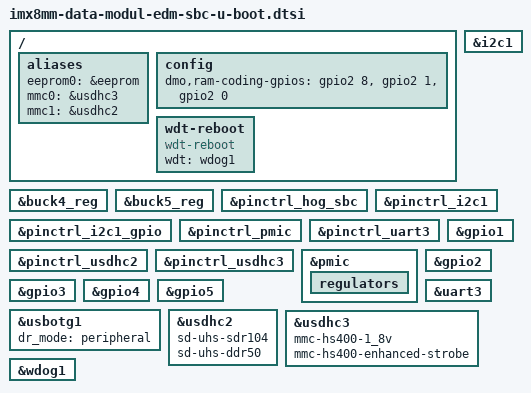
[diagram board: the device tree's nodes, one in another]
// SPDX-License-Identifier: GPL-2.0+
/*
 * Copyright 2022 Marek Vasut <marex@denx.de>
 */

#include "imx8mm-u-boot.dtsi"

/ {
	aliases {
		eeprom0 = &eeprom;
		mmc0 = &usdhc3;	/* eMMC */
		mmc1 = &usdhc2;	/* MicroSD */
	};

	config {
		dmo,ram-coding-gpios = <&gpio2 8 0>, <&gpio2 1 0>, <&gpio2 0 0>;
	};

	wdt-reboot {
		compatible = "wdt-reboot";
		wdt = <&wdog1>;
		bootph-pre-ram;
	};
};

&buck4_reg {
	bootph-pre-ram;
};

&buck5_reg {
	bootph-pre-ram;
};

&i2c1 {
	bootph-pre-ram;
};

&pinctrl_hog_sbc {
	bootph-pre-ram;
};

&pinctrl_i2c1 {
	bootph-pre-ram;
};

&pinctrl_i2c1_gpio {
	bootph-pre-ram;
};

&pinctrl_pmic {
	bootph-pre-ram;
};

&pinctrl_uart3 {
	bootph-pre-ram;
};

&pinctrl_usdhc2 {
	bootph-pre-ram;
};

&pinctrl_usdhc3 {
	bootph-pre-ram;
};

&pmic {
	bootph-pre-ram;

	regulators {
		bootph-pre-ram;
	};
};

&gpio1 {
	bootph-pre-ram;
};

&gpio2 {
	bootph-pre-ram;
};

&gpio3 {
	bootph-pre-ram;
};

&gpio4 {
	bootph-pre-ram;
};

&gpio5 {
	bootph-pre-ram;
};

&uart3 {
	bootph-pre-ram;
};

&usbotg1 {
	dr_mode = "peripheral";
};

&usdhc2 {
	bootph-pre-ram;
	sd-uhs-sdr104;
	sd-uhs-ddr50;
};

&usdhc3 {
	bootph-pre-ram;
	mmc-hs400-1_8v;
	mmc-hs400-enhanced-strobe;
};

&wdog1 {
	bootph-pre-ram;
};
